# MSPM0L130X register map
Vendor: Texas Instruments; File version: This preliminary header file does not have a version number - build date: 2024-04-29 21:56:11
CPU: CM0 r0p1, little endian, MPU, no FPU, 3 interrupt priority bits
Registers are 32-bit, read-write, reset 0x0 unless marked. A register's access mark holds for its fields unless they carry their own. Offsets are from the block's base; [hi:lo] are bit positions; lines under a group give offsets from that group; {n}, {i} and the like mark numbered series; 'fields as' and 'values as' point back to an identical list.

## CPUSS — CPUSSMMR
Base 0x40400000
0x10E0 CPUSS_EVT_MODE ro — Event Mode
  [1:0] INT_CFG — Event line mode select
    0=DISABLE (The interrupt or event line is disabled.); 1=SOFTWARE (Event handled by software. Software must clear the associated RIS flag.); 2=HARDWARE (Event handled by hardware. The hardware (another module) clears automatically the associated RIS flag.)
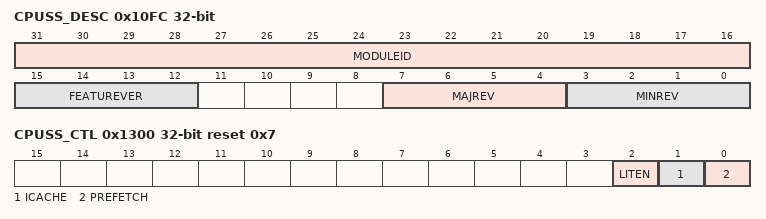
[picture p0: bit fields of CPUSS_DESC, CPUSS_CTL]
0x10FC CPUSS_DESC ro — Module Description
  [31:16] MODULEID — Module identification contains a unique peripheral identification number. The assignments are maintained in a central database for all of the platform modules to ensure uniqueness.
  [15:12] FEATUREVER — Feature Set for the module *instance*
  [7:4] MAJREV — Major rev of the IP
  [3:0] MINREV — Minor rev of the IP
{0x1100+0x2C*i} CPUSS_INT_GROUP0[{i}] (i=0..0) group
  0x00 CPUSS_INT_GROUP0_IIDX ro — Interrupt index
    [7:0] STAT — Interrupt index status
      0=NO_INTR (No pending interrupt); {v}=INT{v-1} (Interrupt {v-1}) (v=1..8)
  0x08 CPUSS_INT_GROUP0_IMASK ro reset 0xFF — Interrupt mask
    [7:0] INT — Masks the corresponding interrupt
      0=CLR (Interrupt is masked out); 1=SET (Interrupt will request an interrupt service routine and corresponding bit in MIS will be set)
  0x10 CPUSS_INT_GROUP0_RIS ro — Raw interrupt status
    [7:0] INT — Raw interrupt status for INT
      0=CLR (INT0 did not occur.); 1=SET (INT0 occurred.)
  0x18 CPUSS_INT_GROUP0_MIS ro — Masked interrupt status
    [0] INT — Masked interrupt status for INT0
      0=CLR (INT does not request an interrupt service routine); 1=SET (INT requests an interrupt service routine)
  0x20 CPUSS_INT_GROUP0_ISET wo — Interrupt set
    [0] INT — Sets INT in RIS register
      0=NO_EFFECT (Writing a 0 has no effect); 1=SET (RIS bit corresponding to INT is set)
  0x28 CPUSS_INT_GROUP0_ICLR wo — Interrupt clear
    [0] INT — Clears INT in RIS register
      0=NO_EFFECT (Writing a 0 has no effect); 1=CLR (RIS bit corresponding to INT is cleared)
{0x1130+0x2C*i} CPUSS_INT_GROUP1[{i}] (i=0..0) group
  0x00 CPUSS_INT_GROUP1_IIDX ro — Interrupt index
    fields as CPUSS_INT_GROUP0[0].CPUSS_INT_GROUP0_IIDX
  0x08 CPUSS_INT_GROUP1_IMASK ro reset 0xFF — Interrupt mask
    fields as CPUSS_INT_GROUP0[0].CPUSS_INT_GROUP0_IMASK
  0x10 CPUSS_INT_GROUP1_RIS ro — Raw interrupt status
    [0] INT — Raw interrupt status for INT
      0=CLR (INT0 did not occur.); 1=SET (INT0 occurred.)
  0x18 CPUSS_INT_GROUP1_MIS ro — Masked interrupt status
    fields as CPUSS_INT_GROUP0[0].CPUSS_INT_GROUP0_MIS
  0x20 CPUSS_INT_GROUP1_ISET wo — Interrupt set
    fields as CPUSS_INT_GROUP0[0].CPUSS_INT_GROUP0_ISET
  0x28 CPUSS_INT_GROUP1_ICLR wo — Interrupt clear
    fields as CPUSS_INT_GROUP0[0].CPUSS_INT_GROUP0_ICLR
0x1300 CPUSS_CTL reset 0x7 — Prefetch/Cache control
  [2] LITEN — Literal caching and prefetch enable. This bit is a subset of ICACHE/PREFETCH bit i.e. literal caching or literal prefetching will only happen if ICACHE or PREFETCH bits have been set respectively When enabled, the cache and prefetcher structures inside CPUSS will cache and prefetch literals When disabled, the cache and prefetcher structures inside CPUSS will not cache and prefetch literals
    0=DISABLE (Literal caching disabled); 1=ENABLE (Literal caching enabled)
  [1] ICACHE — Used to enable/disable Instruction caching on flash access.
    0=DISABLE (Disable instruction caching.); 1=ENABLE (Enable instruction caching.)
  [0] PREFETCH — Used to enable/disable instruction prefetch to Flash.
    0=DISABLE (Disable instruction prefetch.); 1=ENABLE (Enable instruction prefetch.)

## IOMUX — PERIPHERALREGION
Base 0x40428000
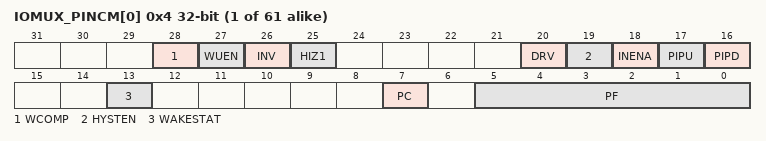
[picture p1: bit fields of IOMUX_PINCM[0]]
{0x4+4i} IOMUX_PINCM[{i}] (i=0..60) — Pin Control Management Register in SECCFG region
  [28] WCOMP — Wakeup Compare Value bit
    0=MATCH0 (Wakeup on a match of 0); 1=MATCH1 (Wakeup on a match of 1)
  [27] WUEN — Wakeup Enable bit
    0=DISABLE (wakeup is disabled.); 1=ENABLE (wakeup is enabled)
  [26] INV — Data inversion selection
    0=DISABLE (Data inversion is disabled.); 1=ENABLE (Data inversion is enabled)
  [25] HIZ1 — High output value will tri-state the output when this bit is enabled
    0=DISABLE (open-drain is disabled.); 1=ENABLE (open-drain is enabled.)
  [20] DRV — Drive strength control selection, for HS IOCELL only
    0=DRVVAL0 (Drive setting of 0 selected); 1=DRVVAL1 (Drive setting of 1 selected)
  [19] HYSTEN — Hystersis Enable Control Selection
    0=DISABLE (hysteresis is disabled.); 1=ENABLE (hysteresis is enabled)
  [18] INENA — Input Enable Control Selection
    0=DISABLE (Input enable is disabled.); 1=ENABLE (Input enable is enabled.)
  [17] PIPU — Pull Up control selection
    0=DISABLE (Pull up is disabled.); 1=ENABLE (Pull up is enabled)
  [16] PIPD — Pull Down control selection
    0=DISABLE (Pull down is disabled.); 1=ENABLE (Pull down is enabled)
  [13] WAKESTAT ro — This has the IOPAD WAKEUP signal as status bit.
    0=DISABLE (wakeup source is NOT from this IOCELL); 1=ENABLE (wakeup source is from this IOCELL)
  [7] PC — Peripheral is Connected
    0=UNCONNECTED (The output of the peripheral (and its output enable) will not propagate to the IOCELL); 1=CONNECTED (The output latch of the dataflow will be transparent)
  [5:0] PF — P channel Function selection bits

## ADC0_SVT — PERIPHERALREGIONSVT
Base 0x4055A000
0x556160 ADC0_SVT_FIFODATA ro — FIFO Data Register
{0x556280+4i} ADC0_SVT_MEMRES[{i}] (i=0..3) ro — Memory Result Register
  [15:0] DATA — MEMRES result register. If DF = 0, unsigned binary: The conversion results are right aligned. In 10 and 8 bit modes, the unused MSB bits are forced to 0. If DF = 1, 2s-complement format: The conversion results are left aligned. In 10 and 8 bit modes, the unused LSB bits are forced to 0. The data is stored in the right-justified format and is converted to the left-justified 2s-complement format during read back.
